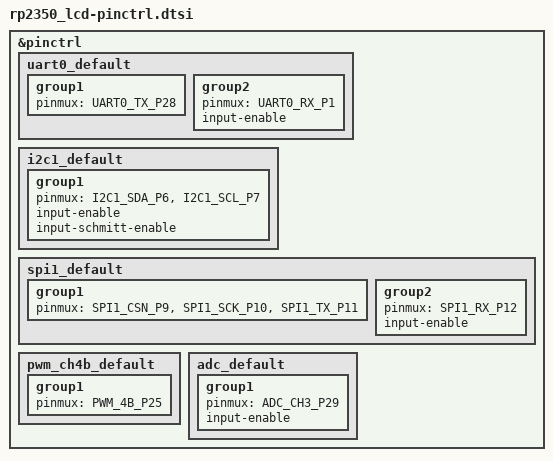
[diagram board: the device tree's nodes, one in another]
/*
 * Copyright (c) 2025 Jared Woolston
 * SPDX-License-Identifier: Apache-2.0
 */

#include <zephyr/dt-bindings/pinctrl/rpi-pico-rp2350a-pinctrl.h>

&pinctrl {
	uart0_default: uart0_default {
		group1 {
			pinmux = <UART0_TX_P28>;
		};
		group2 {
			pinmux = <UART0_RX_P1>;
			input-enable;
		};
	};

	i2c1_default: i2c1_default {
		group1 {
			pinmux = <I2C1_SDA_P6>, <I2C1_SCL_P7>;
			input-enable;
			input-schmitt-enable;
		};
	};

	spi1_default: spi1_default {
		group1 {
			pinmux = <SPI1_CSN_P9>, <SPI1_SCK_P10>, <SPI1_TX_P11>;
		};
		group2 {
			pinmux = <SPI1_RX_P12>;
			input-enable;
		};
	};

	pwm_ch4b_default: pwm_ch4b_default {
		group1 {
			pinmux = <PWM_4B_P25>;
		};
	};

	adc_default: adc_default {
		group1 {
			pinmux = <ADC_CH3_P29>;
			input-enable;
		};
	};
};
